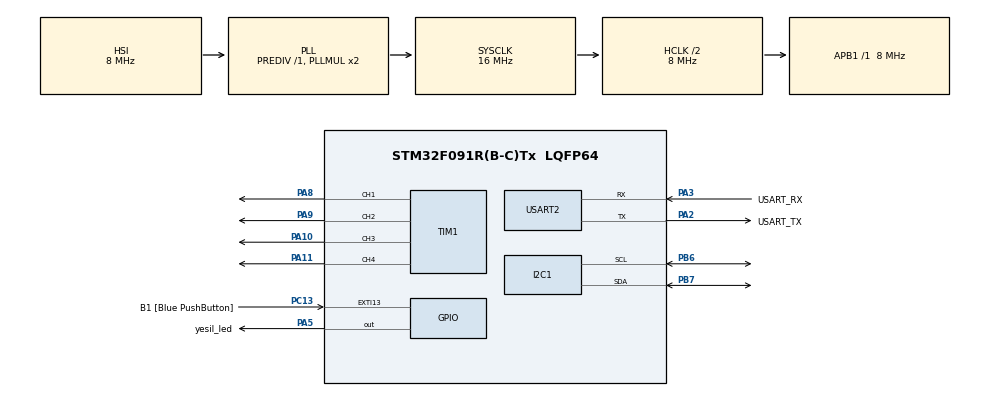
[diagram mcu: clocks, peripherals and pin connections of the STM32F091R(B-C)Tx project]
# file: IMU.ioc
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Dma.Request0=USART2_RX
Dma.USART2_RX.0.Direction=DMA_PERIPH_TO_MEMORY
Dma.USART2_RX.0.Instance=DMA1_Channel1
Dma.USART2_RX.0.MemDataAlignment=DMA_MDATAALIGN_BYTE
Dma.USART2_RX.0.MemInc=DMA_MINC_ENABLE
Dma.USART2_RX.0.Mode=DMA_CIRCULAR
Dma.USART2_RX.0.PeriphDataAlignment=DMA_PDATAALIGN_BYTE
Dma.USART2_RX.0.PeriphInc=DMA_PINC_DISABLE
Dma.USART2_RX.0.Priority=DMA_PRIORITY_LOW
FREERTOS.Queues01=rpc_queue,8,rpc_message_t,0,Static,rpc_queue_buffer,rpc_queue_control_block
FREERTOS.Tasks01=imu_task,24,128,imu_thread,As weak,NULL,Dynamic,NULL,NULL;rpc_task,24,128,rpc_thread,As weak,NULL,Dynamic,NULL,NULL
FREERTOS.configUSE_NEWLIB_REENTRANT=1
I2C1.Timing=0x00201D2B
Mcu.Family=STM32F0
Mcu.Name=STM32F091R(B-C)Tx
Mcu.Package=LQFP64
Mcu.UserConstants=PWM_PREDIV,48;PWM_PERIOD,20000
NVIC.DMA1_Ch1_IRQn=true\:3\:0\:false\:false\:true\:true\:false\:true\:true
NVIC.TIM2_IRQn=true\:3\:0\:false\:false\:true\:false\:false\:true\:true
NVIC.TimeBase=TIM2_IRQn
NVIC.TimeBaseIP=TIM2
PA10.Signal=S_TIM1_CH3
PA11.Signal=S_TIM1_CH4
PA13.GPIO_Label=TMS
PA13.Mode=Serial_Wire
PA13.Signal=SYS_SWDIO
PA14.GPIO_Label=TCK
PA14.Mode=Serial_Wire
PA14.Signal=SYS_SWCLK
PA2.GPIO_Label=USART_TX
PA2.GPIO_Mode=GPIO_MODE_AF_PP
PA2.GPIO_PuPd=GPIO_NOPULL
PA2.GPIO_Speed=GPIO_SPEED_FREQ_LOW
PA2.Mode=Asynchronous
PA2.Signal=USART2_TX
PA3.GPIO_Label=USART_RX
PA3.GPIO_Mode=GPIO_MODE_AF_PP
PA3.GPIO_PuPd=GPIO_NOPULL
PA3.GPIO_Speed=GPIO_SPEED_FREQ_LOW
PA3.Mode=Asynchronous
PA3.Signal=USART2_RX
PA5.GPIO_Label=yesil_led
PA5.GPIO_Mode=GPIO_MODE_OUTPUT_PP
PA5.GPIO_PuPd=GPIO_NOPULL
PA5.GPIO_Speed=GPIO_SPEED_FREQ_LOW
PA5.Signal=GPIO_Output
PA8.Signal=S_TIM1_CH1
PA9.Signal=S_TIM1_CH2
PB6.Mode=I2C
PB6.Signal=I2C1_SCL
PB7.Mode=I2C
PB7.Signal=I2C1_SDA
PC13.GPIO_Label=B1 [Blue PushButton]
PC13.GPIO_ModeDefaultEXTI=GPIO_MODE_IT_FALLING
PC13.Signal=GPXTI13
PC14OSC32_IN.Mode=LSE-External-Oscillator
PC14OSC32_IN.Signal=RCC_OSC32_IN
PC15OSC32_OUT.Mode=LSE-External-Oscillator
PC15OSC32_OUT.Signal=RCC_OSC32_OUT
PF0-OSC_IN.Mode=HSE-External-Clock-Source
PF0-OSC_IN.Signal=RCC_OSC_IN
PF1-OSC_OUT.Signal=RCC_OSC_OUT
ProjectManager.HeapSize=0x200
ProjectManager.StackSize=0x400
ProjectManager.TargetToolchain=STM32CubeIDE
RCC.AHBCLKDivider=RCC_SYSCLK_DIV2
RCC.AHBFreq_Value=8000000
RCC.APB1Freq_Value=8000000
RCC.APB1TimFreq_Value=8000000
RCC.FLatency-AdvancedSettings=FLASH_LATENCY_0
RCC.HCLKFreq_Value=8000000
RCC.PREFETCH_ENABLE-AdvancedSettings=1
RCC.SYSCLKFreq_VALUE=16000000
RCC.SYSCLKSource=RCC_SYSCLKSOURCE_PLLCLK
SH.S_TIM1_CH1.0=TIM1_CH1,PWM Generation1 CH1
SH.S_TIM1_CH2.0=TIM1_CH2,PWM Generation2 CH2
SH.S_TIM1_CH3.0=TIM1_CH3,PWM Generation3 CH3
SH.S_TIM1_CH4.0=TIM1_CH4,PWM Generation4 CH4
TIM1.Channel-PWM\ Generation1\ CH1=TIM_CHANNEL_1
TIM1.Channel-PWM\ Generation2\ CH2=TIM_CHANNEL_2
TIM1.Channel-PWM\ Generation3\ CH3=TIM_CHANNEL_3
TIM1.Channel-PWM\ Generation4\ CH4=TIM_CHANNEL_4
TIM1.Period=PWM_PERIOD - 1
TIM1.Prescaler=PWM_PREDIV - 1
USART2.VirtualMode=VM_ASYNC
USART2.VirtualMode-Asynchronous=VM_ASYNC
VP_FREERTOS_VS_CMSIS_V2.Mode=CMSIS_V2
VP_SYS_VS_tim2.Mode=TIM2
board=NUCLEO-F091RC

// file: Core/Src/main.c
/* USER CODE BEGIN Header */
/**
 ******************************************************************************
 * @file           : main.c
 * @brief          : Main program body
 ******************************************************************************
 * @attention
 *
 * Copyright (c) 2025 STMicroelectronics.
 * All rights reserved.
 *
 * This software is licensed under terms that can be found in the LICENSE file
 * in the root directory of this software component.
 * If no LICENSE file comes with this software, it is provided AS-IS.
 *
 ******************************************************************************
 */
/* USER CODE END Header */
#include "main.h"
#include "cmsis_os.h"
#include "dma.h"
#include "i2c.h"
#include "tim.h"
#include "usart.h"
#include "gpio.h"

/* USER CODE BEGIN Includes */
#include "sensors.h"
#include "stdio.h"

//MS5837_HandleTypeDef depthSensor;
//float                surfacePressure;
/* USER CODE END Includes */

void SystemClock_Config(void);
void MX_FREERTOS_Init(void);

int main(void)
{

  /* MCU Configuration--------------------------------------------------------*/

  /* Reset of all peripherals, Initializes the Flash interface and the Systick. */
  HAL_Init();

  /* Configure the system clock */
  SystemClock_Config();

  /* Initialize all configured peripherals */
  MX_GPIO_Init();
  MX_DMA_Init();
  MX_USART2_UART_Init();
  MX_I2C1_Init();
  MX_TIM1_Init();

  /* Init scheduler */
  osKernelInitialize();

  /* Call init function for freertos objects (in cmsis_os2.c) */
  MX_FREERTOS_Init();

//  ITG3205_Init();
//  printf("– ITG init bitti\r\n");
//
//  ADXL345_Init();
//  printf("– ADXL init bitti\r\n");
//
//  HMC5883L_Init();
//  printf("– HMC init bitti\r\n");
//
//  MS5837_Init(&depthSensor, &hi2c1, 0);
//  MS5837_SetDensity(&depthSensor, 0.99802f);

  /* Start scheduler */
  osKernelStart();

  /* We should never get here as control is now taken by the scheduler */

  /* Infinite loop */
    while (1)
    {

    }
}

void SystemClock_Config(void)
{
  RCC_OscInitTypeDef RCC_OscInitStruct = {0};
  RCC_ClkInitTypeDef RCC_ClkInitStruct = {0};
  RCC_PeriphCLKInitTypeDef PeriphClkInit = {0};

  /** Initializes the RCC Oscillators according to the specified parameters
  * in the RCC_OscInitTypeDef structure.
  */
  RCC_OscInitStruct.OscillatorType = RCC_OSCILLATORTYPE_HSI;
  RCC_OscInitStruct.HSIState = RCC_HSI_ON;
  RCC_OscInitStruct.HSICalibrationValue = RCC_HSICALIBRATION_DEFAULT;
  RCC_OscInitStruct.PLL.PLLState = RCC_PLL_ON;
  RCC_OscInitStruct.PLL.PLLSource = RCC_PLLSOURCE_HSI;
  RCC_OscInitStruct.PLL.PLLMUL = RCC_PLL_MUL2;
  RCC_OscInitStruct.PLL.PREDIV = RCC_PREDIV_DIV1;
  if (HAL_RCC_OscConfig(&RCC_OscInitStruct) != HAL_OK)
  {
    Error_Handler();
  }

  /** Initializes the CPU, AHB and APB buses clocks
  */
  RCC_ClkInitStruct.ClockType = RCC_CLOCKTYPE_HCLK|RCC_CLOCKTYPE_SYSCLK
                              |RCC_CLOCKTYPE_PCLK1;
  RCC_ClkInitStruct.SYSCLKSource = RCC_SYSCLKSOURCE_PLLCLK;
  RCC_ClkInitStruct.AHBCLKDivider = RCC_SYSCLK_DIV2;
  RCC_ClkInitStruct.APB1CLKDivider = RCC_HCLK_DIV1;

  if (HAL_RCC_ClockConfig(&RCC_ClkInitStruct, FLASH_LATENCY_0) != HAL_OK)
  {
    Error_Handler();
  }
  PeriphClkInit.PeriphClockSelection = RCC_PERIPHCLK_USART2|RCC_PERIPHCLK_I2C1;
  PeriphClkInit.Usart2ClockSelection = RCC_USART2CLKSOURCE_PCLK1;
  PeriphClkInit.I2c1ClockSelection = RCC_I2C1CLKSOURCE_HSI;
  if (HAL_RCCEx_PeriphCLKConfig(&PeriphClkInit) != HAL_OK)
  {
    Error_Handler();
  }
}

void HAL_TIM_PeriodElapsedCallback(TIM_HandleTypeDef *htim)
{
  if (htim->Instance == TIM2)
  {
    HAL_IncTick();
  }
}

void Error_Handler(void)
{
    __disable_irq();
    while (1)
    {
    }
}

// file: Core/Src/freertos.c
/* USER CODE BEGIN Header */
/**
 ******************************************************************************
 * File Name          : freertos.c
 * Description        : Code for freertos applications
 ******************************************************************************
 * @attention
 *
 * Copyright (c) 2025 STMicroelectronics.
 * All rights reserved.
 *
 * This software is licensed under terms that can be found in the LICENSE file
 * in the root directory of this software component.
 * If no LICENSE file comes with this software, it is provided AS-IS.
 *
 ******************************************************************************
 */
/* USER CODE END Header */

#include "FreeRTOS.h"
#include "task.h"
#include "main.h"
#include "cmsis_os.h"

typedef StaticQueue_t osStaticMessageQDef_t;

/* Definitions for imu_task */
osThreadId_t imu_taskHandle;

const osThreadAttr_t imu_task_attributes = {
  .name = "imu_task",
  .stack_size = 128 * 4,
  .priority = (osPriority_t) osPriorityNormal,
};
/* Definitions for rpc_task */
osThreadId_t rpc_taskHandle;
const osThreadAttr_t rpc_task_attributes = {
  .name = "rpc_task",
  .stack_size = 128 * 4,
  .priority = (osPriority_t) osPriorityNormal,
};
/* Definitions for rpc_queue */
osMessageQueueId_t rpc_queueHandle;
uint8_t rpc_queue_buffer[ 8 * sizeof( rpc_message_t ) ];
osStaticMessageQDef_t rpc_queue_control_block;
const osMessageQueueAttr_t rpc_queue_attributes = {
  .name = "rpc_queue",
  .cb_mem = &rpc_queue_control_block,
  .cb_size = sizeof(rpc_queue_control_block),
  .mq_mem = &rpc_queue_buffer,
  .mq_size = sizeof(rpc_queue_buffer)
};

void imu_thread(void *argument);
void rpc_thread(void *argument);

void MX_FREERTOS_Init(void); /* (MISRA C 2004 rule 8.1) */

void MX_FREERTOS_Init(void) {

  /* Create the queue(s) */
  /* creation of rpc_queue */
  rpc_queueHandle = osMessageQueueNew (8, sizeof(rpc_message_t), &rpc_queue_attributes);

  /* Create the thread(s) */
  /* creation of imu_task */
  imu_taskHandle = osThreadNew(imu_thread, NULL, &imu_task_attributes);

  /* creation of rpc_task */
  rpc_taskHandle = osThreadNew(rpc_thread, NULL, &rpc_task_attributes);

}

__weak void imu_thread(void *argument)
{
    for (;;)
    {
        osDelay(1);
    }
}

__weak void rpc_thread(void *argument)
{
    for (;;)
    {
        osDelay(1);
    }
}
